# ADuCM320 register map
Vendor: Analog Devices Inc.; Series: ARMCM3; File version: 1.1
CPU: CM3 r2p1, little endian, no MPU, no FPU, 3 interrupt priority bits
Registers are 16-bit, read-write, no defined reset value unless marked. A register's access mark holds for its fields unless they carry their own. Offsets are from the block's base; [hi:lo] are bit positions; {n}, {i} and the like mark numbered series.

## GPIO1 — General Purpose Input Output 1
Base 0x40020040
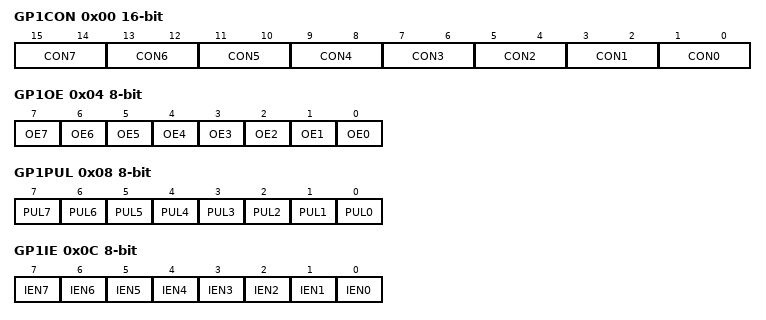
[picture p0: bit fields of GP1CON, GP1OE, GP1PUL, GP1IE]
0x00 GP1CON — GPIO Port 1 configuration
  [15:14] CON7 — p1.7 configuration bits
    0=GPIOIRQ1; 1=PWM5; 2=SPI1CS; 3=PLAO7
  [13:12] CON6 — p1.6 configuration bits
    0=GPIO; 1=PWM4; 2=SPI1MOSI; 3=PLAO6
  [11:10] CON5 — p1.5 configuration bits
    0=GPIO; 1=PWM3; 2=SPI1MISO; 3=PLAO5
  [9:8] CON4 — p1.4 configuration bits
    0=GPIO; 1=PWM2; 2=SPISCLK (SPI1 SCLK); 3=PLAO4
  [7:6] CON3 — p1.3 configuration bits
    0=GPIO; 1=PWM1; 3=PLAI7
  [5:4] CON2 — p1.2 configuration bits
    0=GPIO; 1=PWM0; 3=PLAI6
  [3:2] CON1 — p1.1 configuration bits
    0=GPIO; 1=UARTSOUT; 2=PLACLK1; 3=PLAI5
  [1:0] CON0 — p1.0 configuration bits
    0=GPIO; 1=UARTSIN; 2=ECLKIN (External Clock Input); 3=PLAI4
0x04 GP1OE 8-bit — GPIO Port 1 output enable
  [all] fields
    0=DIS; 1=EN
  [n] OE{n} (n=0..7) — Pin Output Drive enable
0x08 GP1PUL 8-bit — GPIO Port 1 pullup enable
  [all] fields
    0=DIS; 1=EN
  [n] PUL{n} (n=0..7) — Pin Pull up enable
0x0C GP1IE 8-bit — GPIO Port 1 input path enable
  [all] fields
    0=DIS; 1=EN
  [n] IEN{n} (n=0..7) — Input path enable
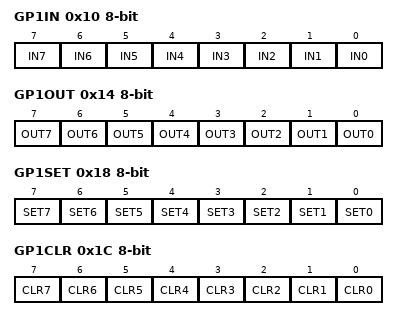
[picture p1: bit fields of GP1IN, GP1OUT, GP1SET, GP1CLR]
0x10 GP1IN 8-bit ro — GPIO Port 1 registered data input
  [all] fields
    0=LOW; 1=HIGH
  [n] IN{n} (n=0..7) — Registered data input
0x14 GP1OUT 8-bit — GPIO Port 1 data output
  [all] fields
    0=LOW; 1=HIGH
  [n] OUT{n} (n=0..7) — Data out
0x18 GP1SET 8-bit wo — GPIO Port 1 data out set
  [all] fields
    1=SET
  [n] SET{n} (n=0..7) — Set the output HIGH for the pin
0x1C GP1CLR 8-bit wo — GPIO Port 1 data out clear
  [all] fields
    1=CLR
  [n] CLR{n} (n=0..7) — Set the output low for the port pin
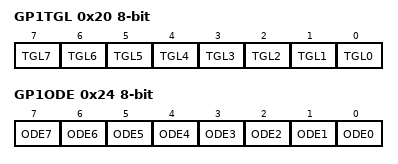
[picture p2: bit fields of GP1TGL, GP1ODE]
0x20 GP1TGL 8-bit wo — GPIO Port 1 pin toggle
  [all] fields
    1=TGL
  [n] TGL{n} (n=0..7) — Toggle the output of the port pin
0x24 GP1ODE 8-bit — GPIO Port 1 open drain enable
  [all] fields
    0=DIS; 1=EN
  [n] ODE{n} (n=0..7) — Open drain enable

## GPIO2 — General Purpose Input Output 2
Base 0x40020080
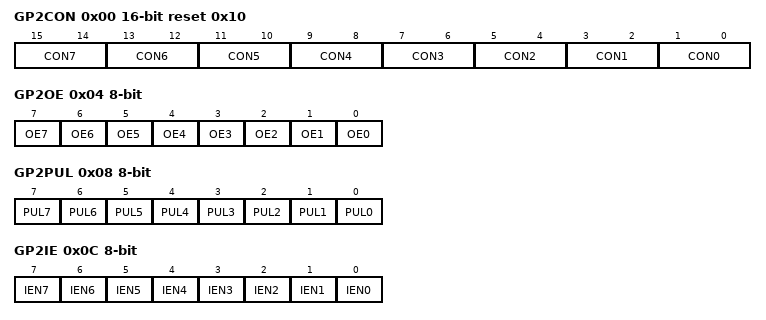
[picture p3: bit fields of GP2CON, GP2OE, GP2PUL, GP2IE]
0x00 GP2CON reset 0x10 (reset mask 0x0) — GPIO Port 2 configuration
  [15:14] CON7 — p2.7 configuration bits
    0=GPIOIRQ8; 3=PLAO11
  [13:12] CON6 — p2.6 configuration bits
    0=GPIOIRQ7; 3=PLAO10
  [11:10] CON5 — p2.5 configuration bits
    0=GPIOIRQ6; 2=PWM7; 3=PLAO9
  [9:8] CON4 — p2.4 configuration bits
    0=GIPOIRQ5 (GPIO/IRQ5); 1=ADCCONVSTIN (ADC_CONVST input); 2=PWM6; 3=PLAO8
  [7:6] CON3 — p2.3 configuration bits
    0=GPIOBM
  [5:4] CON2 — p2.2 configuration bits
    0=GPIOIRQ4; 2=EXTCLKOUT (External Clock output); 3=PLAI10
  [3:2] CON1 — p2.1 configuration bits
    0=GPIOIRQ3; 1=PWMSYNC; 3=PLAI9
  [1:0] CON0 — p2.0 configuration bits
    0=GPIOIRQ2; 1=PWMTRIP; 2=PLACLK2; 3=PLAI8
0x04 GP2OE 8-bit — GPIO Port 2 output enable
  [all] fields
    0=DIS; 1=EN
  [n] OE{n} (n=0..7) — Pin Output Drive enable
0x08 GP2PUL 8-bit — GPIO Port 2 pullup enable
  [all] fields
    0=DIS; 1=EN
  [n] PUL{n} (n=0..7) — Pin Pull up enable
0x0C GP2IE 8-bit — GPIO Port 2 input path enable
  [all] fields
    0=DIS; 1=EN
  [n] IEN{n} (n=0..7) — Input path enable
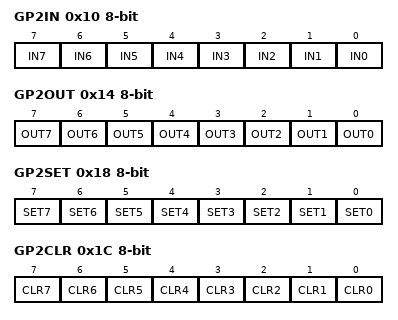
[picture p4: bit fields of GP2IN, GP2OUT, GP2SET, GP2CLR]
0x10 GP2IN 8-bit ro — GPIO Port 2 registered data input
  [all] fields
    0=LOW; 1=HIGH
  [n] IN{n} (n=0..7) — Registered data input
0x14 GP2OUT 8-bit — GPIO Port 2 data output
  [all] fields
    0=LOW; 1=HIGH
  [n] OUT{n} (n=0..7) — Data out
0x18 GP2SET 8-bit wo — GPIO Port 2 data out set
  [all] fields
    1=SET
  [n] SET{n} (n=0..7) — Set the output HIGH for the pin
0x1C GP2CLR 8-bit wo — GPIO Port 2 data out clear
  [all] fields
    1=CLR
  [n] CLR{n} (n=0..7) — Set the output low for the port pin
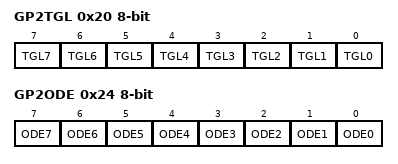
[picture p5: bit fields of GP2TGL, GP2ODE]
0x20 GP2TGL 8-bit wo — GPIO Port 2 pin toggle
  [all] fields
    1=TGL
  [n] TGL{n} (n=0..7) — Toggle the output of the port pin
0x24 GP2ODE 8-bit — GPIO Port 2 open drain enable
  [all] fields
    0=DIS; 1=EN
  [n] ODE{n} (n=0..7) — Open drain enable
